# G32F002 register map
File version: 1.0
CPU: CM0PLUS r0p1, little endian, no MPU, no FPU, 4 interrupt priority bits
Registers are 32-bit, read-write, reset 0x0 unless marked. A register's access mark holds for its fields unless they carry their own. Offsets are from the block's base; lines under a group give offsets from that group; [hi:lo] are bit positions; {n}, {i} and the like mark numbered series; 'fields as' and 'values as' point back to an identical list; <NAME> marks a mode.

## Memory map
0x40000000 ATMR size 0x400 — Advance timer
0x40001000 BTMR size 0x400 — Base timer
0x40002000 I2C size 0x400 — Inter-Integrated Circuit
0x40003000 SPI size 0x400 — Serial peripheral interface
0x40004000 USART size 0x400 — Universal asynchronous receiver transmitter
0x40005000 COMP0 size 0x400 — Comparator
0x40006000 COMP1 size 0x400 — Comparator
0x40008000 IWDT size 0x400 — Independent watchdog
0x40009000 EINT size 0x400 — External interrupt/event controller
0x4000A000 LPTMR size 0x400 — Low-power timer
0x4000B000 ADC size 0x400 — Analog-to-digital converter
0x40020000 SCU size 0x400 — System configuration controller
0x40020400 FLASH size 0x400 — Flash memory controller
0x40020800 CRC size 0x400 — Cryptographic processor
0x40020C00 GPIOA size 0x400 — General-purpose I/Os
0x40021000 GPIOB size 0x400 — General-purpose I/Os

## Interrupts
1 PVD (SCU) — PVD global interrupt
3 FLASH — FLASH global interrupt
4 RCM (SCU) — RCM global interrupt
5 EINT0_1 (EINT) — EINT Line 0 to 1 global interrupt
6 EINT2_3 (EINT) — EINT Line 2 to 3 global interrupt
7 EINT4_15 (EINT) — EINT Line 4 to 15 global interrupts
12 ADC — ADC global interrupt
13 ATMR_BRK_UP_TRG_COM (ATMR) — ATMR_BRK_UP_TRG_COM global interrupt
14 ATMR_CC (ATMR) — ATMR_CC global interrupt
17 BTMR — BTMR global interrupt
19 LPTMR — LPTMR global interrupt
21 COMP0 — COMP0 global interrupt
22 COMP1 — COMP1 global interrupt
23 I2C1 (I2C) — I2C1 global interrupt
25 SPI1 (SPI) — SPI1 global interrupt
27 USART — USART global interrupt

## SCU — System configuration controller
Base 0x40020000
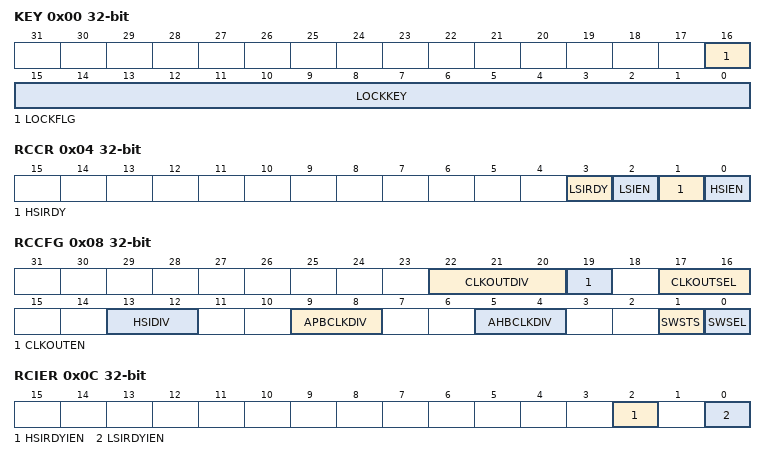
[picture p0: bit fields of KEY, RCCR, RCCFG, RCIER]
0x00 KEY
  [16] LOCKFLG — System register KEY protection status bit.
  [15:0] LOCKKEY — Configuration of password protection for system register write operations.
0x04 RCCR access per field
  [3] LSIRDY ro — LSI READY FLAG
  [2] LSIEN rw — LSI enable
  [1] HSIRDY ro — HSI READY FLAG
  [0] HSIEN rw — HSI enable
0x08 RCCFG access per field
  [22:20] CLKOUTDIV rw — CLKOUT clock frequency output
  [19] CLKOUTEN rw — Clock output enable
  [17:16] CLKOUTSEL rw — CLKOUT clock output selection
  [13:12] HSIDIV rw — HSI clock division.
  [9:8] APBCLKDIV rw — APB clock division.
  [5:4] AHBCLKDIV rw — AHB clock division.
  [1] SWSTS ro — System Clock Status
  [0] SWSEL rw — System Clock Selection
0x0C RCIER
  [2] HSIRDYIEN — HSI-ready interrupt enable
  [0] LSIRDYIEN — LSI-ready interrupt enable
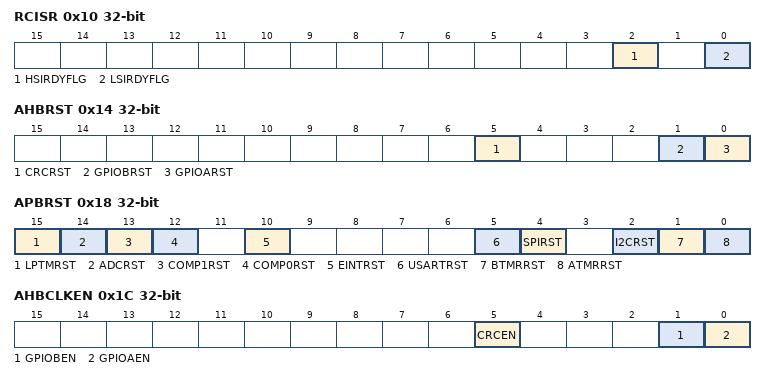
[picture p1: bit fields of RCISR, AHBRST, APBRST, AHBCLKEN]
0x10 RCISR
  [2] HSIRDYFLG — HSI-ready flag
  [0] LSIRDYFLG — LSI-ready flag
0x14 AHBRST
  [5] CRCRST — CRC module reset
  [1] GPIOBRST — GPIOB module reset
  [0] GPIOARST — GPIOA module reset
0x18 APBRST
  [15] LPTMRST — LPTMR module reset
  [14] ADCRST — ADC module reset
  [13] COMP1RST — COMP1 module reset
  [12] COMP0RST — COMP0 module reset
  [10] EINTRST — EINT module reset
  [5] USARTRST — USART module reset
  [4] SPIRST — SPI module reset
  [2] I2CRST — I2C module reset
  [1] BTMRRST — BTMR module reset
  [0] ATMRRST — ATMR module reset
0x1C AHBCLKEN
  [5] CRCEN — CRC clock enable
  [1] GPIOBEN — GPIOB clock enable
  [0] GPIOAEN — GPIOA clock enable
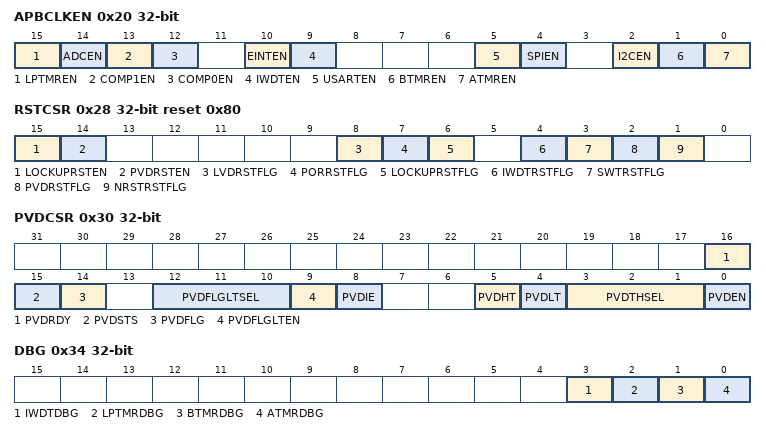
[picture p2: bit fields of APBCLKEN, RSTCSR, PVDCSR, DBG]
0x20 APBCLKEN
  [15] LPTMREN — LPTMR module enable
  [14] ADCEN — ADC module enable
  [13] COMP1EN — COMP1 module enable
  [12] COMP0EN — COMP0 module enable
  [10] EINTEN — EINT module enable
  [9] IWDTEN — IWDT module enable
  [5] USARTEN — USART module enable
  [4] SPIEN — SPI module enable
  [2] I2CEN — I2C module enable
  [1] BTMREN — BTMR module enable
  [0] ATMREN — ATMR module enable
0x24 NRSTCR
  [1:0] NRSTCRSEL — NRST filter select
0x28 RSTCSR reset 0x80
  [15] LOCKUPRSTEN — /
  [14] PVDRSTEN — /
  [8] LVDRSTFLG — /
  [7] PORRSTFLG — Power reset caused by.
  [6] LOCKUPRSTFLG — /
  [4] IWDTRSTFLG — Reset caused by independent watchdog.
  [3] SWTRSTFLG — Software-induced reset
  [2] PVDRSTFLG — /
  [1] NRSTRSTFLG — Reset caused by external RST pin.
0x2C ADCCR
  [1:0] ADCCLKDIV — /
0x30 PVDCSR
  [16] PVDRDY — /
  [15] PVDSTS — /
  [14] PVDFLG — /
  [12:10] PVDFLGLTSEL — /
  [9] PVDFLGLTEN — /
  [8] PVDIE — /
  [5] PVDHT — /
  [4] PVDLT — /
  [3:1] PVDTHSEL — /
  [0] PVDEN — /
0x34 DBG
  [3] IWDTDBG — /
  [2] LPTMRDBG — /
  [1] BTMRDBG — /
  [0] ATMRDBG — /
